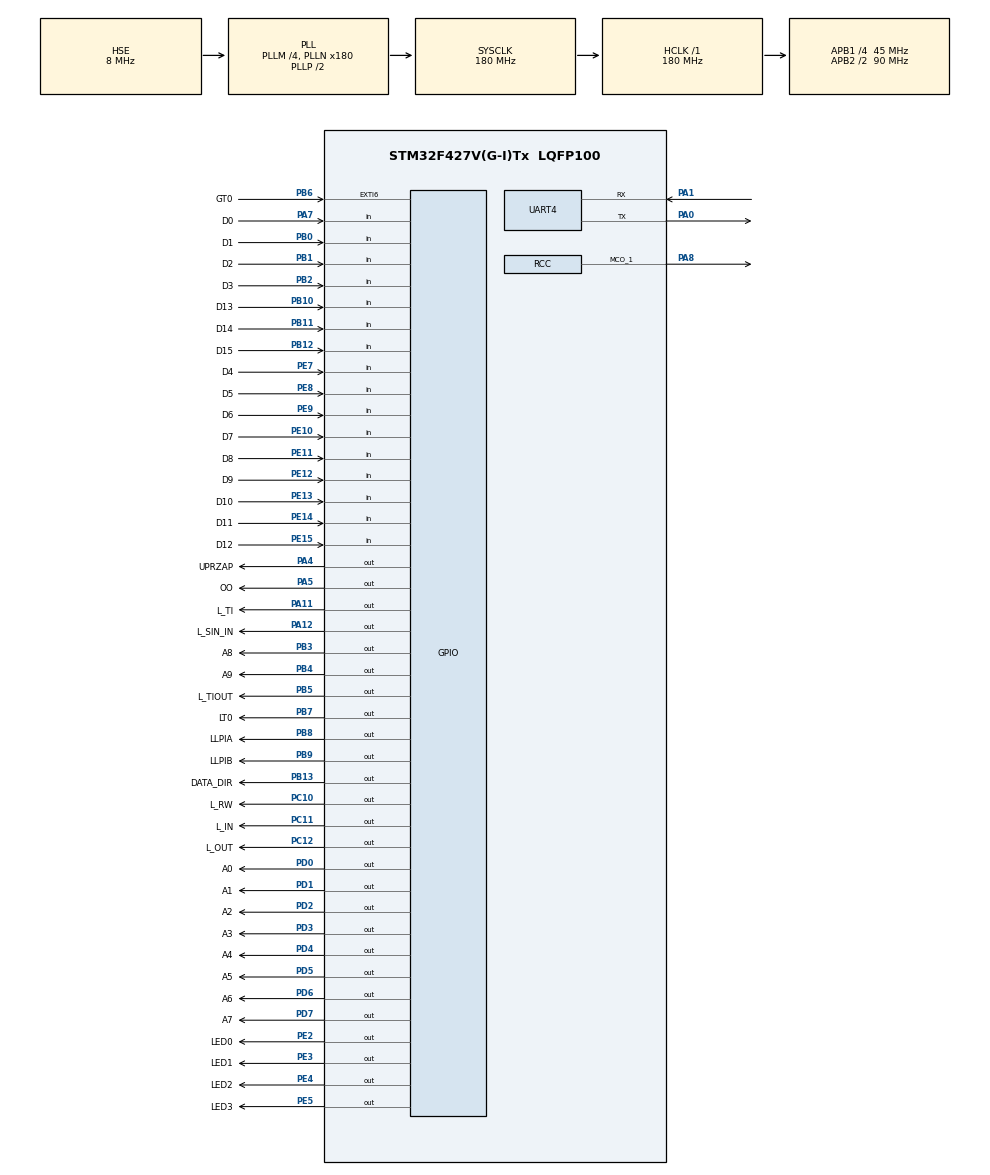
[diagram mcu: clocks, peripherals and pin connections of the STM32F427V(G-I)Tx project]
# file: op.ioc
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Dma.Request0=UART4_TX
Dma.Request1=UART4_RX
Dma.UART4_RX.1.Direction=DMA_PERIPH_TO_MEMORY
Dma.UART4_RX.1.FIFOMode=DMA_FIFOMODE_DISABLE
Dma.UART4_RX.1.Instance=DMA1_Stream2
Dma.UART4_RX.1.MemDataAlignment=DMA_MDATAALIGN_BYTE
Dma.UART4_RX.1.MemInc=DMA_MINC_ENABLE
Dma.UART4_RX.1.Mode=DMA_NORMAL
Dma.UART4_RX.1.PeriphDataAlignment=DMA_PDATAALIGN_BYTE
Dma.UART4_RX.1.PeriphInc=DMA_PINC_DISABLE
Dma.UART4_RX.1.Priority=DMA_PRIORITY_LOW
Dma.UART4_TX.0.Direction=DMA_MEMORY_TO_PERIPH
Dma.UART4_TX.0.FIFOMode=DMA_FIFOMODE_DISABLE
Dma.UART4_TX.0.Instance=DMA1_Stream4
Dma.UART4_TX.0.MemDataAlignment=DMA_MDATAALIGN_BYTE
Dma.UART4_TX.0.MemInc=DMA_MINC_ENABLE
Dma.UART4_TX.0.Mode=DMA_NORMAL
Dma.UART4_TX.0.PeriphDataAlignment=DMA_PDATAALIGN_BYTE
Dma.UART4_TX.0.PeriphInc=DMA_PINC_DISABLE
Dma.UART4_TX.0.Priority=DMA_PRIORITY_LOW
Mcu.Family=STM32F4
Mcu.Name=STM32F427V(G-I)Tx
Mcu.Package=LQFP100
NVIC.DMA1_Stream2_IRQn=true\:0\:0\:false\:false\:true\:false\:true\:true
NVIC.DMA1_Stream4_IRQn=true\:0\:0\:false\:false\:true\:false\:true\:true
NVIC.PriorityGroup=NVIC_PRIORITYGROUP_4
NVIC.TIM1_BRK_TIM9_IRQn=true\:0\:0\:false\:false\:true\:true\:true\:true
NVIC.TIM4_IRQn=true\:0\:0\:false\:false\:true\:true\:true\:true
NVIC.UART4_IRQn=true\:0\:0\:true\:false\:true\:true\:true\:true
PA0/WKUP.Mode=Asynchronous
PA0/WKUP.Signal=UART4_TX
PA1.Mode=Asynchronous
PA1.Signal=UART4_RX
PA11.GPIO_Label=L_TI
PA11.GPIO_Speed=GPIO_SPEED_FREQ_HIGH
PA11.Signal=GPIO_Output
PA12.GPIO_Label=L_SIN_IN
PA12.GPIO_Speed=GPIO_SPEED_FREQ_HIGH
PA12.Signal=GPIO_Output
PA4.GPIO_Label=UPRZAP
PA4.GPIO_Speed=GPIO_SPEED_FREQ_HIGH
PA4.Signal=GPIO_Output
PA5.GPIO_Label=OO
PA5.GPIO_Speed=GPIO_SPEED_FREQ_HIGH
PA5.Signal=GPIO_Output
PA7.GPIO_Label=D0
PA7.Signal=GPIO_Input
PA8.Mode=Clock-out-1
PA8.Signal=RCC_MCO_1
PB0.GPIO_Label=D1
PB0.Signal=GPIO_Input
PB1.GPIO_Label=D2
PB1.Signal=GPIO_Input
PB10.GPIO_Label=D13
PB10.Signal=GPIO_Input
PB11.GPIO_Label=D14
PB11.Signal=GPIO_Input
PB12.GPIO_Label=D15
PB12.Signal=GPIO_Input
PB13.GPIO_Label=DATA_DIR
PB13.GPIO_PuPd=GPIO_PULLUP
PB13.GPIO_Speed=GPIO_SPEED_FREQ_HIGH
PB13.PinState=GPIO_PIN_SET
PB13.Signal=GPIO_Output
PB2/BOOT1.GPIO_Label=D3
PB2/BOOT1.Signal=GPIO_Input
PB3.GPIO_Label=A8
PB3.GPIO_Speed=GPIO_SPEED_FREQ_HIGH
PB3.Signal=GPIO_Output
PB4.GPIO_Label=A9
PB4.GPIO_Speed=GPIO_SPEED_FREQ_HIGH
PB4.Signal=GPIO_Output
PB5.GPIO_Label=L_TIOUT
PB5.GPIO_Speed=GPIO_SPEED_FREQ_HIGH
PB5.Signal=GPIO_Output
PB6.GPIO_Label=GT0
PB6.Signal=GPXTI6
PB7.GPIO_Label=LT0
PB7.GPIO_Speed=GPIO_SPEED_FREQ_HIGH
PB7.Signal=GPIO_Output
PB8.GPIO_Label=LLPIA
PB8.GPIO_Speed=GPIO_SPEED_FREQ_HIGH
PB8.Signal=GPIO_Output
PB9.GPIO_Label=LLPIB
PB9.GPIO_Speed=GPIO_SPEED_FREQ_HIGH
PB9.Signal=GPIO_Output
PC10.GPIO_Label=L_RW
PC10.GPIO_Speed=GPIO_SPEED_FREQ_HIGH
PC10.Signal=GPIO_Output
PC11.GPIO_Label=L_IN
PC11.GPIO_Speed=GPIO_SPEED_FREQ_HIGH
PC11.Signal=GPIO_Output
PC12.GPIO_Label=L_OUT
PC12.GPIO_Speed=GPIO_SPEED_FREQ_HIGH
PC12.Signal=GPIO_Output
PD0.GPIO_Label=A0
PD0.GPIO_Speed=GPIO_SPEED_FREQ_HIGH
PD0.Signal=GPIO_Output
PD1.GPIO_Label=A1
PD1.GPIO_Speed=GPIO_SPEED_FREQ_HIGH
PD1.Signal=GPIO_Output
PD2.GPIO_Label=A2
PD2.GPIO_Speed=GPIO_SPEED_FREQ_HIGH
PD2.Signal=GPIO_Output
PD3.GPIO_Label=A3
PD3.GPIO_Speed=GPIO_SPEED_FREQ_HIGH
PD3.Signal=GPIO_Output
PD4.GPIO_Label=A4
PD4.GPIO_Speed=GPIO_SPEED_FREQ_HIGH
PD4.Signal=GPIO_Output
PD5.GPIO_Label=A5
PD5.GPIO_Speed=GPIO_SPEED_FREQ_HIGH
PD5.Signal=GPIO_Output
PD6.GPIO_Label=A6
PD6.GPIO_Speed=GPIO_SPEED_FREQ_HIGH
PD6.Signal=GPIO_Output
PD7.GPIO_Label=A7
PD7.GPIO_Speed=GPIO_SPEED_FREQ_HIGH
PD7.Signal=GPIO_Output
PE10.GPIO_Label=D7
PE10.Signal=GPIO_Input
PE11.GPIO_Label=D8
PE11.Signal=GPIO_Input
PE12.GPIO_Label=D9
PE12.Signal=GPIO_Input
PE13.GPIO_Label=D10
PE13.Signal=GPIO_Input
PE14.GPIO_Label=D11
PE14.Signal=GPIO_Input
PE15.GPIO_Label=D12
PE15.Signal=GPIO_Input
PE2.GPIO_Label=LED0
PE2.Signal=GPIO_Output
PE3.GPIO_Label=LED1
PE3.Signal=GPIO_Output
PE4.GPIO_Label=LED2
PE4.Signal=GPIO_Output
PE5.GPIO_Label=LED3
PE5.Signal=GPIO_Output
PE7.GPIO_Label=D4
PE7.Signal=GPIO_Input
PE8.GPIO_Label=D5
PE8.Signal=GPIO_Input
PE9.GPIO_Label=D6
PE9.Signal=GPIO_Input
PH0/OSC_IN.Mode=HSE-External-Oscillator
PH0/OSC_IN.Signal=RCC_OSC_IN
PH1/OSC_OUT.Mode=HSE-External-Oscillator
PH1/OSC_OUT.Signal=RCC_OSC_OUT
ProjectManager.HeapSize=0x200
ProjectManager.StackSize=0x400
ProjectManager.TargetToolchain=STM32CubeIDE
RCC.48MHZClocksFreq_Value=90000000
RCC.AHBFreq_Value=180000000
RCC.APB1CLKDivider=RCC_HCLK_DIV4
RCC.APB1Freq_Value=45000000
RCC.APB1TimFreq_Value=90000000
RCC.APB2CLKDivider=RCC_HCLK_DIV2
RCC.APB2Freq_Value=90000000
RCC.APB2TimFreq_Value=180000000
RCC.CortexFreq_Value=180000000
RCC.EnbaleCSS=true
RCC.HCLKFreq_Value=180000000
RCC.HSE_VALUE=8000000
RCC.HSI_VALUE=16000000
RCC.LSE_VALUE=32768
RCC.PLLM=4
RCC.PLLN=180
RCC.PLLSourceVirtual=RCC_PLLSOURCE_HSE
RCC.RCC_MCO1Source=RCC_MCO1SOURCE_HSE
RCC.RCC_MCODiv1=RCC_MCODIV_4
RCC.SYSCLKFreq_VALUE=180000000
RCC.SYSCLKSource=RCC_SYSCLKSOURCE_PLLCLK
RCC.VCOOutputFreq_Value=360000000
TIM4.Period=7199
TIM4.Prescaler=127
TIM9.Period=1499
TIM9.Prescaler=179
UART4.Parity=PARITY_NONE
UART4.VirtualMode=Asynchronous
UART4.WordLength=WORDLENGTH_8B
VP_TIM4_VS_ClockSourceINT.Mode=Internal
VP_TIM9_VS_ClockSourceINT.Mode=Internal
board=custom

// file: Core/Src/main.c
/* USER CODE BEGIN Header */
/**
  ******************************************************************************
  * @file           : main.c
  * @brief          : Main program body
  ******************************************************************************
  * @attention
  *
  * Copyright (c) 2024 STMicroelectronics.
  * All rights reserved.
  *
  * This software is licensed under terms that can be found in the LICENSE file
  * in the root directory of this software component.
  * If no LICENSE file comes with this software, it is provided AS-IS.
  *
  ******************************************************************************
  */
/* USER CODE END Header */
#include "main.h"

TIM_HandleTypeDef htim4;
TIM_HandleTypeDef htim9;

UART_HandleTypeDef huart4;
DMA_HandleTypeDef hdma_uart4_tx;
DMA_HandleTypeDef hdma_uart4_rx;

/* USER CODE BEGIN PV */

uint16_t uspu_buttons[USPU_BUTTON_SIZE];
uint16_t uspu_leds[USPU_LED_SIZE];
uint16_t acps[ACPS_SIZE];
uint16_t op_data[OP_DATA_SIZE];
uint16_t op_command;
uint16_t oo_delay;
uint8_t upr_zap_count;
/* USER CODE END PV */

void SystemClock_Config(void);
static void MX_GPIO_Init(void);
static void MX_DMA_Init(void);
static void MX_UART4_Init(void);
static void MX_TIM4_Init(void);
static void MX_TIM9_Init(void);

/* USER CODE BEGIN 0 */
uint8_t rx_buffer[RX_BUFFER_SIZE];
/* USER CODE END 0 */

int main(void)
{

  /* MCU Configuration--------------------------------------------------------*/

  /* Reset of all peripherals, Initializes the Flash interface and the Systick. */
  HAL_Init();

  /* Configure the system clock */
  SystemClock_Config();

  /* Initialize all configured peripherals */
  MX_GPIO_Init();
  MX_DMA_Init();
  MX_UART4_Init();
  MX_TIM4_Init();
  MX_TIM9_Init();
  /* USER CODE BEGIN 2 */
  buffer_direction_in();
  HAL_TIM_Base_Start_IT(&htim4);
  HAL_TIM_Base_Start_IT(&htim9);
  HAL_UART_Receive_DMA(&huart4, rx_buffer, RX_BUFFER_SIZE);
  /* USER CODE END 2 */

  /* Infinite loop */
  while (1)
  {

  }
}

void SystemClock_Config(void)
{
  RCC_OscInitTypeDef RCC_OscInitStruct = {0};
  RCC_ClkInitTypeDef RCC_ClkInitStruct = {0};

  /** Configure the main internal regulator output voltage
  */
  __HAL_RCC_PWR_CLK_ENABLE();
  __HAL_PWR_VOLTAGESCALING_CONFIG(PWR_REGULATOR_VOLTAGE_SCALE1);

  /** Initializes the RCC Oscillators according to the specified parameters
  * in the RCC_OscInitTypeDef structure.
  */
  RCC_OscInitStruct.OscillatorType = RCC_OSCILLATORTYPE_HSE;
  RCC_OscInitStruct.HSEState = RCC_HSE_ON;
  RCC_OscInitStruct.PLL.PLLState = RCC_PLL_ON;
  RCC_OscInitStruct.PLL.PLLSource = RCC_PLLSOURCE_HSE;
  RCC_OscInitStruct.PLL.PLLM = 4;
  RCC_OscInitStruct.PLL.PLLN = 180;
  RCC_OscInitStruct.PLL.PLLP = RCC_PLLP_DIV2;
  RCC_OscInitStruct.PLL.PLLQ = 4;
  if (HAL_RCC_OscConfig(&RCC_OscInitStruct) != HAL_OK)
  {
    Error_Handler();
  }

  /** Activate the Over-Drive mode
  */
  if (HAL_PWREx_EnableOverDrive() != HAL_OK)
  {
    Error_Handler();
  }

  /** Initializes the CPU, AHB and APB buses clocks
  */
  RCC_ClkInitStruct.ClockType = RCC_CLOCKTYPE_HCLK|RCC_CLOCKTYPE_SYSCLK
                              |RCC_CLOCKTYPE_PCLK1|RCC_CLOCKTYPE_PCLK2;
  RCC_ClkInitStruct.SYSCLKSource = RCC_SYSCLKSOURCE_PLLCLK;
  RCC_ClkInitStruct.AHBCLKDivider = RCC_SYSCLK_DIV1;
  RCC_ClkInitStruct.APB1CLKDivider = RCC_HCLK_DIV4;
  RCC_ClkInitStruct.APB2CLKDivider = RCC_HCLK_DIV2;

  if (HAL_RCC_ClockConfig(&RCC_ClkInitStruct, FLASH_LATENCY_5) != HAL_OK)
  {
    Error_Handler();
  }
  HAL_RCC_MCOConfig(RCC_MCO1, RCC_MCO1SOURCE_HSE, RCC_MCODIV_4);

  /** Enables the Clock Security System
  */
  HAL_RCC_EnableCSS();
}

static void MX_TIM4_Init(void)
{

  TIM_ClockConfigTypeDef sClockSourceConfig = {0};
  TIM_MasterConfigTypeDef sMasterConfig = {0};

  htim4.Instance = TIM4;
  htim4.Init.Prescaler = 127;
  htim4.Init.CounterMode = TIM_COUNTERMODE_UP;
  htim4.Init.Period = 7199;
  htim4.Init.ClockDivision = TIM_CLOCKDIVISION_DIV1;
  htim4.Init.AutoReloadPreload = TIM_AUTORELOAD_PRELOAD_DISABLE;
  if (HAL_TIM_Base_Init(&htim4) != HAL_OK)
  {
    Error_Handler();
  }
  sClockSourceConfig.ClockSource = TIM_CLOCKSOURCE_INTERNAL;
  if (HAL_TIM_ConfigClockSource(&htim4, &sClockSourceConfig) != HAL_OK)
  {
    Error_Handler();
  }
  sMasterConfig.MasterOutputTrigger = TIM_TRGO_RESET;
  sMasterConfig.MasterSlaveMode = TIM_MASTERSLAVEMODE_DISABLE;
  if (HAL_TIMEx_MasterConfigSynchronization(&htim4, &sMasterConfig) != HAL_OK)
  {
    Error_Handler();
  }

}

static void MX_TIM9_Init(void)
{

  TIM_ClockConfigTypeDef sClockSourceConfig = {0};

  htim9.Instance = TIM9;
  htim9.Init.Prescaler = 179;
  htim9.Init.CounterMode = TIM_COUNTERMODE_UP;
  htim9.Init.Period = 1499;
  htim9.Init.ClockDivision = TIM_CLOCKDIVISION_DIV1;
  htim9.Init.AutoReloadPreload = TIM_AUTORELOAD_PRELOAD_DISABLE;
  if (HAL_TIM_Base_Init(&htim9) != HAL_OK)
  {
    Error_Handler();
  }
  sClockSourceConfig.ClockSource = TIM_CLOCKSOURCE_INTERNAL;
  if (HAL_TIM_ConfigClockSource(&htim9, &sClockSourceConfig) != HAL_OK)
  {
    Error_Handler();
  }

}

static void MX_UART4_Init(void)
{

  huart4.Instance = UART4;
  huart4.Init.BaudRate = 115200;
  huart4.Init.WordLength = UART_WORDLENGTH_8B;
  huart4.Init.StopBits = UART_STOPBITS_1;
  huart4.Init.Parity = UART_PARITY_NONE;
  huart4.Init.Mode = UART_MODE_TX_RX;
  huart4.Init.HwFlowCtl = UART_HWCONTROL_NONE;
  huart4.Init.OverSampling = UART_OVERSAMPLING_16;
  if (HAL_UART_Init(&huart4) != HAL_OK)
  {
    Error_Handler();
  }

}

static void MX_DMA_Init(void)
{

  /* DMA controller clock enable */
  __HAL_RCC_DMA1_CLK_ENABLE();

  /* DMA interrupt init */
  /* DMA1_Stream2_IRQn interrupt configuration */
  HAL_NVIC_SetPriority(DMA1_Stream2_IRQn, 0, 0);
  HAL_NVIC_EnableIRQ(DMA1_Stream2_IRQn);
  /* DMA1_Stream4_IRQn interrupt configuration */
  HAL_NVIC_SetPriority(DMA1_Stream4_IRQn, 0, 0);
  HAL_NVIC_EnableIRQ(DMA1_Stream4_IRQn);

}

static void MX_GPIO_Init(void)
{
  GPIO_InitTypeDef GPIO_InitStruct = {0};

  /* GPIO Ports Clock Enable */
  __HAL_RCC_GPIOE_CLK_ENABLE();
  __HAL_RCC_GPIOH_CLK_ENABLE();
  __HAL_RCC_GPIOA_CLK_ENABLE();
  __HAL_RCC_GPIOB_CLK_ENABLE();
  __HAL_RCC_GPIOC_CLK_ENABLE();
  __HAL_RCC_GPIOD_CLK_ENABLE();

  /*Configure GPIO pin Output Level */
  HAL_GPIO_WritePin(GPIOE, LED0_Pin|LED1_Pin|LED2_Pin|LED3_Pin, GPIO_PIN_RESET);

  /*Configure GPIO pin Output Level */
  HAL_GPIO_WritePin(GPIOA, UPRZAP_Pin|OO_Pin|L_TI_Pin|L_SIN_IN_Pin, GPIO_PIN_RESET);

  /*Configure GPIO pin Output Level */
  HAL_GPIO_WritePin(DATA_DIR_GPIO_Port, DATA_DIR_Pin, GPIO_PIN_SET);

  /*Configure GPIO pin Output Level */
  HAL_GPIO_WritePin(GPIOC, L_RW_Pin|L_IN_Pin|L_OUT_Pin, GPIO_PIN_RESET);

  /*Configure GPIO pin Output Level */
  HAL_GPIO_WritePin(GPIOD, A0_Pin|A1_Pin|A2_Pin|A3_Pin
                          |A4_Pin|A5_Pin|A6_Pin|A7_Pin, GPIO_PIN_RESET);

  /*Configure GPIO pin Output Level */
  HAL_GPIO_WritePin(GPIOB, A8_Pin|A9_Pin|L_TIOUT_Pin|LT0_Pin
                          |LLPIA_Pin|LLPIB_Pin, GPIO_PIN_RESET);

  /*Configure GPIO pins : LED0_Pin LED1_Pin LED2_Pin LED3_Pin */
  GPIO_InitStruct.Pin = LED0_Pin|LED1_Pin|LED2_Pin|LED3_Pin;
  GPIO_InitStruct.Mode = GPIO_MODE_OUTPUT_PP;
  GPIO_InitStruct.Pull = GPIO_NOPULL;
  GPIO_InitStruct.Speed = GPIO_SPEED_FREQ_LOW;
  HAL_GPIO_Init(GPIOE, &GPIO_InitStruct);

  /*Configure GPIO pins : UPRZAP_Pin OO_Pin L_TI_Pin L_SIN_IN_Pin */
  GPIO_InitStruct.Pin = UPRZAP_Pin|OO_Pin|L_TI_Pin|L_SIN_IN_Pin;
  GPIO_InitStruct.Mode = GPIO_MODE_OUTPUT_PP;
  GPIO_InitStruct.Pull = GPIO_NOPULL;
  GPIO_InitStruct.Speed = GPIO_SPEED_FREQ_HIGH;
  HAL_GPIO_Init(GPIOA, &GPIO_InitStruct);

  /*Configure GPIO pin : D0_Pin */
  GPIO_InitStruct.Pin = D0_Pin;
  GPIO_InitStruct.Mode = GPIO_MODE_INPUT;
  GPIO_InitStruct.Pull = GPIO_NOPULL;
  HAL_GPIO_Init(D0_GPIO_Port, &GPIO_InitStruct);

  /*Configure GPIO pins : D1_Pin D2_Pin D3_Pin D13_Pin
                           D14_Pin D15_Pin */
  GPIO_InitStruct.Pin = D1_Pin|D2_Pin|D3_Pin|D13_Pin
                          |D14_Pin|D15_Pin;
  GPIO_InitStruct.Mode = GPIO_MODE_INPUT;
  GPIO_InitStruct.Pull = GPIO_NOPULL;
  HAL_GPIO_Init(GPIOB, &GPIO_InitStruct);

  /*Configure GPIO pins : D4_Pin D5_Pin D6_Pin D7_Pin
                           D8_Pin D9_Pin D10_Pin D11_Pin
                           D12_Pin */
  GPIO_InitStruct.Pin = D4_Pin|D5_Pin|D6_Pin|D7_Pin
                          |D8_Pin|D9_Pin|D10_Pin|D11_Pin
                          |D12_Pin;
  GPIO_InitStruct.Mode = GPIO_MODE_INPUT;
  GPIO_InitStruct.Pull = GPIO_NOPULL;
  HAL_GPIO_Init(GPIOE, &GPIO_InitStruct);

  /*Configure GPIO pin : DATA_DIR_Pin */
  GPIO_InitStruct.Pin = DATA_DIR_Pin;
  GPIO_InitStruct.Mode = GPIO_MODE_OUTPUT_PP;
  GPIO_InitStruct.Pull = GPIO_PULLUP;
  GPIO_InitStruct.Speed = GPIO_SPEED_FREQ_HIGH;
  HAL_GPIO_Init(DATA_DIR_GPIO_Port, &GPIO_InitStruct);

  /*Configure GPIO pin : PA8 */
  GPIO_InitStruct.Pin = GPIO_PIN_8;
  GPIO_InitStruct.Mode = GPIO_MODE_AF_PP;
  GPIO_InitStruct.Pull = GPIO_NOPULL;
  GPIO_InitStruct.Speed = GPIO_SPEED_FREQ_LOW;
  GPIO_InitStruct.Alternate = GPIO_AF0_MCO;
  HAL_GPIO_Init(GPIOA, &GPIO_InitStruct);

  /*Configure GPIO pins : L_RW_Pin L_IN_Pin L_OUT_Pin */
  GPIO_InitStruct.Pin = L_RW_Pin|L_IN_Pin|L_OUT_Pin;
  GPIO_InitStruct.Mode = GPIO_MODE_OUTPUT_PP;
  GPIO_InitStruct.Pull = GPIO_NOPULL;
  GPIO_InitStruct.Speed = GPIO_SPEED_FREQ_HIGH;
  HAL_GPIO_Init(GPIOC, &GPIO_InitStruct);

  /*Configure GPIO pins : A0_Pin A1_Pin A2_Pin A3_Pin
                           A4_Pin A5_Pin A6_Pin A7_Pin */
  GPIO_InitStruct.Pin = A0_Pin|A1_Pin|A2_Pin|A3_Pin
                          |A4_Pin|A5_Pin|A6_Pin|A7_Pin;
  GPIO_InitStruct.Mode = GPIO_MODE_OUTPUT_PP;
  GPIO_InitStruct.Pull = GPIO_NOPULL;
  GPIO_InitStruct.Speed = GPIO_SPEED_FREQ_HIGH;
  HAL_GPIO_Init(GPIOD, &GPIO_InitStruct);

  /*Configure GPIO pins : A8_Pin A9_Pin L_TIOUT_Pin LT0_Pin
                           LLPIA_Pin LLPIB_Pin */
  GPIO_InitStruct.Pin = A8_Pin|A9_Pin|L_TIOUT_Pin|LT0_Pin
                          |LLPIA_Pin|LLPIB_Pin;
  GPIO_InitStruct.Mode = GPIO_MODE_OUTPUT_PP;
  GPIO_InitStruct.Pull = GPIO_NOPULL;
  GPIO_InitStruct.Speed = GPIO_SPEED_FREQ_HIGH;
  HAL_GPIO_Init(GPIOB, &GPIO_InitStruct);

  /*Configure GPIO pin : GT0_Pin */
  GPIO_InitStruct.Pin = GT0_Pin;
  GPIO_InitStruct.Mode = GPIO_MODE_IT_RISING;
  GPIO_InitStruct.Pull = GPIO_NOPULL;
  HAL_GPIO_Init(GT0_GPIO_Port, &GPIO_InitStruct);

}

void Error_Handler(void)
{
  __disable_irq();
  while (1)
  {
  }
}
